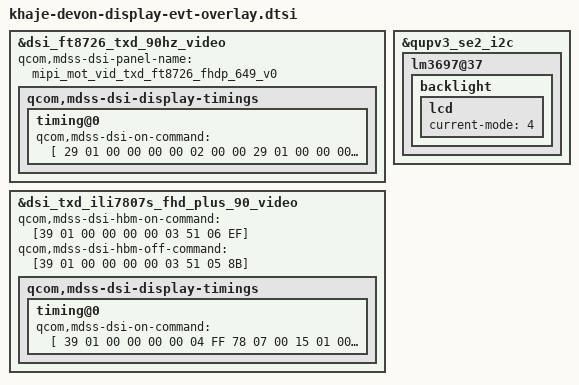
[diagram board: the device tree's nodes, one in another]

&dsi_ft8726_txd_90hz_video {
	qcom,mdss-dsi-panel-name = "mipi_mot_vid_txd_ft8726_fhdp_649_v0";

	qcom,mdss-dsi-display-timings {
		timing@0 {
			qcom,mdss-dsi-on-command = [
				29 01 00 00 00 00 02 00 00
				29 01 00 00 00 00 04 FF 87 20 01
				29 01 00 00 00 00 02 00 80
				29 01 00 00 00 00 03 FF 87 20
				29 01 00 00 00 00 02 00 00
				29 01 00 00 00 00 05 2A 00 00 04 37
				29 01 00 00 00 00 02 00 00
				29 01 00 00 00 00 05 2B 00 00 09 5F
				29 01 00 00 00 00 02 00 A3
				29 01 00 00 00 00 05 B3 09 60 00 18
				29 01 00 00 00 00 02 00 80
				29 01 00 00 00 00 07 C0 00 4D 00 10 00 10
				29 01 00 00 00 00 02 00 90
				29 01 00 00 00 00 07 C0 00 4D 00 10 00 10
				29 01 00 00 00 00 02 00 A0
				29 01 00 00 00 00 07 C0 00 70 00 10 00 10
				29 01 00 00 00 00 02 00 B0
				29 01 00 00 00 00 06 C0 00 D7 00 10 10
				29 01 00 00 00 00 02 00 60
				29 01 00 00 00 00 07 C0 00 B7 00 10 00 10
				29 01 00 00 00 00 02 00 70
				29 01 00 00 00 00 0D C0 00 C4 00 C8 0C 03 14 00 00 14 01 98
				29 01 00 00 00 00 02 00 A3
				29 01 00 00 00 00 07 C1 00 4D 00 21 00 02
				29 01 00 00 00 00 02 00 80
				29 01 00 00 00 00 11 CE 01 81 FF FF 00 B8 00 C8 00 00 00 00 00 B8 00 C8
				29 01 00 00 00 00 02 00 90
				29 01 00 00 00 00 10 CE 00 BD 12 75 00 BD 80 FF FF 00 07 08 0F 0E 00
				29 01 00 00 00 00 02 00 A0
				29 01 00 00 00 00 04 CE 00 00 00
				29 01 00 00 00 00 02 00 B0
				29 01 00 00 00 00 04 CE 22 00 00
				29 01 00 00 00 00 02 00 D1
				29 01 00 00 00 00 08 CE 00 00 01 00 00 00 00
				29 01 00 00 00 00 02 00 E1
				29 01 00 00 00 00 0C CE 03 03 14 03 14 00 00 00 00 00 00
				29 01 00 00 00 00 02 00 F1
				29 01 00 00 00 00 0A CE 29 1F 00 01 2C 01 08 00 00
				29 01 00 00 00 00 02 00 B0
				29 01 00 00 00 00 05 CF 00 00 8F 93
				29 01 00 00 00 00 02 00 B5
				29 01 00 00 00 00 05 CF 04 04 F5 F9
				29 01 00 00 00 00 02 00 C0
				29 01 00 00 00 00 05 CF 09 09 5B 5F
				29 01 00 00 00 00 02 00 C5
				29 01 00 00 00 00 05 CF 09 09 61 65
				29 01 00 00 00 00 02 00 D1
				29 01 00 00 00 00 0D C1 0A A6 0E C8 19 67 07 E3 0B 11 13 04
				29 01 00 00 00 00 02 00 E1
				29 01 00 00 00 00 03 C1 0E C8
				29 01 00 00 00 00 02 00 E4
				29 01 00 00 00 00 0D CF 09 D4 09 D3 09 D3 09 D3 09 D3 09 D3
				29 01 00 00 00 00 02 00 80
				29 01 00 00 00 00 03 C1 44 44
				29 01 00 00 00 00 02 00 90
				29 01 00 00 00 00 02 C1 03
				29 01 00 00 00 00 02 00 F5
				29 01 00 00 00 00 02 CF 02
				29 01 00 00 00 00 02 00 F6
				29 01 00 00 00 00 02 CF 78
				29 01 00 00 00 00 02 00 F0
				29 01 00 00 00 00 03 CF 01 78
				29 01 00 00 00 00 02 00 F0
				29 01 00 00 00 00 02 C1 00
				29 01 00 00 00 00 02 00 CC
				29 01 00 00 00 00 02 C1 18
				29 01 00 00 00 00 02 00 80
				29 01 00 00 00 00 02 C5 88
				29 01 00 00 00 00 02 00 91
				29 01 00 00 00 00 02 C4 08
				29 01 00 00 00 00 02 00 80
				29 01 00 00 00 00 09 C2 83 01 03 82 82 01 03 82
				29 01 00 00 00 00 02 00 A0
				29 01 00 00 00 00 10 C2 8A 07 00 03 84 89 08 00 03 84 88 09 00 03 84
				29 01 00 00 00 00 02 00 B0
				29 01 00 00 00 00 06 C2 87 0A 00 03 84
				29 01 00 00 00 00 02 00 E0
				29 01 00 00 00 00 05 C2 33 33 00 00
				29 01 00 00 00 00 02 00 E8
				29 01 00 00 00 00 09 C2 12 00 0A 0A 1A 88 00 00
				29 01 00 00 00 00 02 00 D0
				29 01 00 00 00 00 11 C3 35 02 00 00 35 02 00 00 35 02 00 00 35 02 00 00
				29 01 00 00 00 00 02 00 E0
				29 01 00 00 00 00 11 C3 35 0A 00 00 35 0A 00 00 35 0A 00 00 35 0A 00 00
				29 01 00 00 00 00 02 00 80
				29 01 00 00 00 00 11 CB CD CD CC 00 CD CC 00 CD CE CE CD 00 CC CC 00 00
				29 01 00 00 00 00 02 00 90
				29 01 00 00 00 00 11 CB 0C 00 00 00 0C 0C 00 00 0C 00 00 00 00 00 00 00
				29 01 00 00 00 00 02 00 A0
				29 01 00 00 00 00 09 CB 00 00 00 00 00 00 00 00
				29 01 00 00 00 00 02 00 B0
				29 01 00 00 00 00 05 CB 50 41 A4 00
				29 01 00 00 00 00 02 00 C0
				29 01 00 00 00 00 05 CB 50 41 A4 00
				29 01 00 00 00 00 02 00 D5
				29 01 00 00 00 00 0C CB 83 00 83 83 00 83 83 00 83 83 00
				29 01 00 00 00 00 02 00 E0
				29 01 00 00 00 00 0E CB 83 83 00 83 83 00 83 83 00 83 83 00 83
				29 01 00 00 00 00 02 00 80
				29 01 00 00 00 00 11 CC 18 17 16 26 07 06 09 08 26 1F 1F 20 20 26 1E 26
				29 01 00 00 00 00 02 00 90
				29 01 00 00 00 00 09 CC 1C 1D 1D 01 03 02 20 20
				29 01 00 00 00 00 02 00 80
				29 01 00 00 00 00 11 CD 18 17 16 26 07 06 09 08 26 1F 1F 20 20 26 1E 26
				29 01 00 00 00 00 02 00 90
				29 01 00 00 00 00 09 CD 1C 1D 1D 01 03 02 20 20
				29 01 00 00 00 00 02 00 A0
				29 01 00 00 00 00 11 CC 18 17 16 26 08 09 07 06 26 1F 1F 1C 1C 26 1E 26
				29 01 00 00 00 00 02 00 B0
				29 01 00 00 00 00 09 CC 20 1D 1D 01 02 03 20 20
				29 01 00 00 00 00 02 00 A0
				29 01 00 00 00 00 11 CD 18 17 16 26 08 09 07 06 26 1F 1F 1C 1C 26 1E 26
				29 01 00 00 00 00 02 00 B0
				29 01 00 00 00 00 09 CD 20 1D 1D 01 02 03 20 20
				29 01 00 00 00 00 02 00 86
				29 01 00 00 00 00 07 C0 01 02 00 01 12 05
				29 01 00 00 00 00 02 00 96
				29 01 00 00 00 00 07 C0 01 02 00 01 12 05
				29 01 00 00 00 00 02 00 A6
				29 01 00 00 00 00 07 C0 01 02 00 01 1B 09
				29 01 00 00 00 00 02 00 A3
				29 01 00 00 00 00 07 CE 01 02 00 01 12 05
				29 01 00 00 00 00 02 00 B3
				29 01 00 00 00 00 07 CE 01 02 00 01 12 05
				29 01 00 00 00 00 02 00 66
				29 01 00 00 00 00 07 C0 01 05 00 01 1F 05
				29 01 00 00 00 00 02 00 93
				29 01 00 00 00 00 02 C5 37
				29 01 00 00 00 00 02 00 97
				29 01 00 00 00 00 02 C5 37
				29 01 00 00 00 00 02 00 9A
				29 01 00 00 00 00 02 C5 23
				29 01 00 00 00 00 02 00 9C
				29 01 00 00 00 00 02 C5 23
				29 01 00 00 00 00 02 00 B6
				29 01 00 00 00 00 09 C5 19 19 0F 0F 19 19 0F 0F
				29 01 00 00 00 00 02 00 00
				29 01 00 00 00 00 03 D8 29 29

				29 01 00 00 00 00 02 00 88
				29 01 00 00 00 00 02 C4 08
				29 01 00 00 00 00 02 00 80
				29 01 00 00 00 00 02 A7 03
				29 01 00 00 00 00 02 00 B1
				29 01 00 00 00 00 02 F5 1F
				29 01 00 00 00 00 02 00 CB
				29 01 00 00 00 00 02 C0 01
				29 01 00 00 00 00 02 00 9B
				29 01 00 00 00 00 02 C4 FF
				29 01 00 00 00 00 02 00 94
				29 01 00 00 00 00 02 E9 FF
				29 01 00 00 00 00 02 00 9A
				29 01 00 00 00 00 02 C4 11
				29 01 00 00 00 00 02 00 95
				29 01 00 00 00 00 02 E9 10
				29 01 00 00 00 00 02 00 00
				29 01 00 00 00 00 29 E1 00 04 08 10 2A 1B 24 2A 35 DF 3E 45 4B 51 68 55 5E 66 6D D1 74 7B 83 8C B9 96 9C A2 AA 48 B2 BD CB D4 F4 DE EE F9 FF C3
				29 01 00 00 00 00 02 00 30
				29 01 00 00 00 00 29 E1 03 05 08 10 0A 1B 24 2A 35 DF 3E 45 4B 51 68 55 5E 66 6D D1 74 7B 83 8C B9 96 9C A2 AA 48 B2 BD CB D4 F4 DE EE F9 FF C3
				29 01 00 00 00 00 02 00 60
				29 01 00 00 00 00 29 E1 00 04 08 10 2A 1B 24 2A 35 DF 3E 45 4B 51 68 55 5E 66 6D D1 74 7B 83 8C B9 96 9C A2 AA 48 B2 BD CB D4 F4 DE EE F9 FF C3
				29 01 00 00 00 00 02 00 90
				29 01 00 00 00 00 29 E1 03 05 08 10 0A 1B 24 2A 35 DF 3E 45 4B 51 68 55 5E 66 6D D1 74 7B 83 8C B9 96 9C A2 AA 48 B2 BD CB D4 F4 DE EE F9 FF C3
				29 01 00 00 00 00 02 00 C0
				29 01 00 00 00 00 29 E1 00 04 08 10 2A 1B 24 2A 35 DF 3E 45 4B 51 68 55 5E 66 6D D1 74 7B 83 8C B9 96 9C A2 AA 48 B2 BD CB D4 F4 DE EE F9 FF C3
				29 01 00 00 00 00 02 00 F0
				29 01 00 00 00 00 11 E1 03 05 08 10 0A 1B 24 2A 35 DF 3E 45 4B 51 68 55
				29 01 00 00 00 00 02 00 00
				29 01 00 00 00 00 19 E2 5E 66 6D D1 74 7B 83 8C B9 96 9C A2 AA 48 B2 BD CB D4 F4 DE EE F9 FF C3
				29 01 00 00 00 00 02 00 8C
				29 01 00 00 00 00 04 C3 00 00 00
				29 01 00 00 00 00 02 00 80
				29 01 00 00 00 00 02 B3 22
				29 01 00 00 00 00 02 00 B0
				29 01 00 00 00 00 02 B3 00
				29 01 00 00 00 00 02 00 83
				29 01 00 00 00 00 02 B0 63
				29 01 00 00 00 00 02 00 82
				29 01 00 00 00 00 02 F5 00
				29 01 00 00 00 00 02 00 93
				29 01 00 00 00 00 02 F5 00
				29 01 00 00 00 00 02 00 9B
				29 01 00 00 00 00 02 F5 49
				29 01 00 00 00 00 02 00 9D
				29 01 00 00 00 00 02 F5 49
				29 01 00 00 00 00 02 00 BE
				29 01 00 00 00 00 03 C5 F0 F0
				29 01 00 00 00 00 02 00 8A
				29 01 00 00 00 00 02 F5 C9
				29 01 00 00 00 00 02 00 99
				29 01 00 00 00 00 02 CF 50
				29 01 00 00 00 00 02 00 9C
				29 01 00 00 00 00 02 F5 00
				29 01 00 00 00 00 02 00 9E
				29 01 00 00 00 00 02 F5 00
				29 01 00 00 00 00 02 00 B0
				29 01 00 00 00 00 07 C5 D0 4A 39 D0 4A 0E
				29 01 00 00 00 00 02 00 8A
				29 01 00 00 00 00 02 C5 02
				29 01 00 00 00 00 02 00 8D
				29 01 00 00 00 00 02 C5 03
				29 01 00 00 00 00 02 00 A0
				29 01 00 00 00 00 02 A5 07
				29 01 00 00 00 00 02 00 E8
				29 01 00 00 00 00 02 C0 40
				29 01 00 00 00 00 02 00 90
				29 01 00 00 00 00 02 A7 16
				29 01 00 00 00 00 02 00 A1
				29 01 00 00 00 00 02 C5 40
				29 01 00 00 00 00 02 00 9D
				29 01 00 00 00 00 02 C5 44
				29 01 00 00 00 00 02 00 98
				29 01 00 00 00 00 02 C5 27
				29 01 00 00 00 00 02 00 A0
				29 01 00 00 00 00 02 C5 40
				29 01 00 00 00 00 02 00 E0
				29 01 00 00 00 00 02 CF 14
				29 01 00 00 00 00 02 00 92
				29 01 00 00 00 00 02 CF 12
				29 01 00 00 00 00 02 00 84
				29 01 00 00 00 00 02 A4 01
				29 01 00 00 00 00 02 00 80
				29 01 00 00 00 00 03 A6 00 12
				29 01 00 00 00 00 02 00 B0
				29 01 00 00 00 00 04 CA 04 04 0B
				29 01 00 00 00 00 02 00 B0
				29 01 00 00 00 00 0F B4 00 08 02 00 00 BB 00 07 0D B7 0C B7 10 F0
				29 01 00 00 00 00 02 00 00
				29 01 00 00 00 00 04 FF FF FF FF
				05 01 00 00 64 00 01 11
				05 01 00 00 0A 00 01 29

				29 01 00 00 00 00 03 51 66 06
				29 01 00 00 00 00 02 53 2C
				29 01 00 00 00 00 02 55 01

				29 01 00 00 00 00 02 35 00
			];
		};
	};
};

&dsi_txd_ili7807s_fhd_plus_90_video {
	qcom,mdss-dsi-hbm-on-command = [39 01 00 00 00 00 03 51 06 EF];
	qcom,mdss-dsi-hbm-off-command = [39 01 00 00 00 00 03 51 05 8B];

	qcom,mdss-dsi-display-timings {
		timing@0 {
			qcom,mdss-dsi-on-command = [
				39 01 00 00 00 00 04 FF 78 07 00
				15 01 00 00 50 00 02 11 00
				39 01 00 00 00 00 04 FF 78 07 06
				15 01 00 00 00 00 02 3E E3
				15 01 00 00 00 00 02 80	00
				15 01 00 00 00 00 02 4E 64
				15 01 00 00 00 00 02 4D 81
				15 01 00 00 00 00 02 C7 05
				15 01 00 00 00 00 02 48 09
				39 01 00 00 00 00 04 FF	78 07 02
				15 01 00 00 00 00 02 1B	01
				39 01 00 00 00 00 04 FF	78 07 00
				39 01 00 00 00 00 03 51 05 8B
				15 01 00 00 00 00 02 53 2C
				15 01 00 00 00 00 02 55 01
				15 01 00 00 0A 00 02 29 00];
		};
	};
};

&qupv3_se2_i2c {
        status = "ok";
        lm3697@37 {
		backlight {
			lcd {
				current-mode = <4>;	/*4: 23.4mA*/
			};
		};
	};
};

